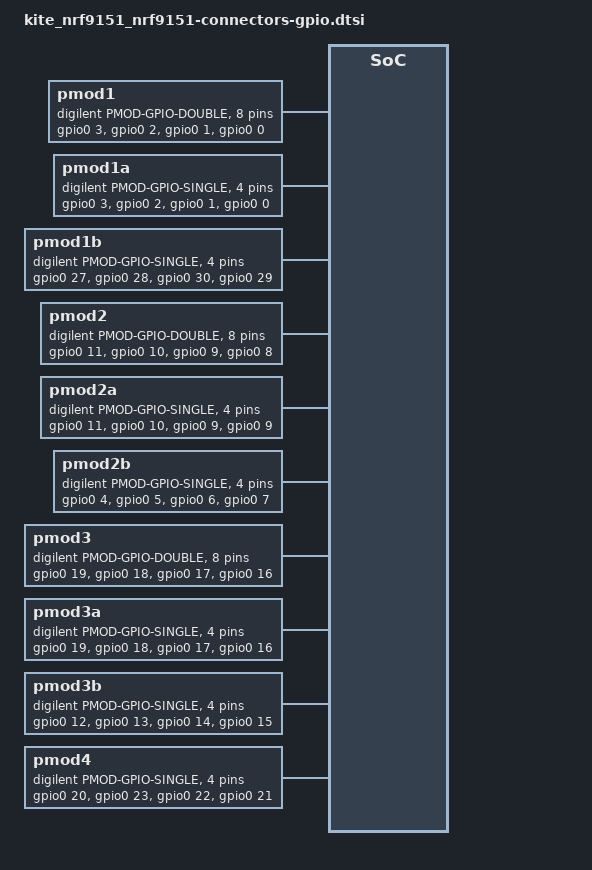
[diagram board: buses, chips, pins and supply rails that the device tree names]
/*
 * NOTE: Autogenerated file using gen-connectors-dtsi.py
 *
 * SPDX-License-Identifier: Apache-2.0
 */

/ {
	pmod1: pmod1-gpio {
		compatible = "digilent,pmod-gpio-double";
		#gpio-cells = <2>;
		gpio-map-mask = <0xffffffff 0xffffffc0>;
		gpio-map-pass-thru = <0 0x3f>;
		gpio-map = <0 0 &gpio0 3 0>,	/* IO1 */
			   <1 0 &gpio0 2 0>,	/* IO2 */
			   <2 0 &gpio0 1 0>,	/* IO3 */
			   <3 0 &gpio0 0 0>,	/* IO4 */
			   <4 0 &gpio0 27 0>,	/* IO5 */
			   <5 0 &gpio0 28 0>,	/* IO6 */
			   <6 0 &gpio0 30 0>,	/* IO7 */
			   <7 0 &gpio0 29 0>;	/* IO8 */
	};

	pmod1a: pmod1a-gpio {
		compatible = "digilent,pmod-gpio-single";
		#gpio-cells = <2>;
		gpio-map-mask = <0xffffffff 0xffffffc0>;
		gpio-map-pass-thru = <0 0x3f>;
		gpio-map = <0 0 &gpio0 3 0>,	/* IO1 */
			   <1 0 &gpio0 2 0>,	/* IO2 */
			   <2 0 &gpio0 1 0>,	/* IO3 */
			   <3 0 &gpio0 0 0>;	/* IO4 */
	};

	pmod1b: pmod1b-gpio {
		compatible = "digilent,pmod-gpio-single";
		#gpio-cells = <2>;
		gpio-map-mask = <0xffffffff 0xffffffc0>;
		gpio-map-pass-thru = <0 0x3f>;
		gpio-map = <0 0 &gpio0 27 0>,	/* IO1 */
			   <1 0 &gpio0 28 0>,	/* IO2 */
			   <2 0 &gpio0 30 0>,	/* IO3 */
			   <3 0 &gpio0 29 0>;	/* IO4 */
	};

	pmod2: pmod2-gpio {
		compatible = "digilent,pmod-gpio-double";
		#gpio-cells = <2>;
		gpio-map-mask = <0xffffffff 0xffffffc0>;
		gpio-map-pass-thru = <0 0x3f>;
		gpio-map = <0 0 &gpio0 11 0>,	/* IO1 */
			   <1 0 &gpio0 10 0>,	/* IO2 */
			   <2 0 &gpio0 9 0>,	/* IO3 */
			   <3 0 &gpio0 8 0>,	/* IO4 */
			   <4 0 &gpio0 4 0>,	/* IO5 */
			   <5 0 &gpio0 5 0>,	/* IO6 */
			   <6 0 &gpio0 6 0>,	/* IO7 */
			   <7 0 &gpio0 7 0>;	/* IO8 */
	};

	pmod2a: pmod2a-gpio {
		compatible = "digilent,pmod-gpio-single";
		#gpio-cells = <2>;
		gpio-map-mask = <0xffffffff 0xffffffc0>;
		gpio-map-pass-thru = <0 0x3f>;
		gpio-map = <0 0 &gpio0 11 0>,	/* IO1 */
			   <1 0 &gpio0 10 0>,	/* IO2 */
			   <2 0 &gpio0 9 0>,	/* IO3 */
			   <3 0 &gpio0 9 0>;	/* IO4 */
	};

	pmod2b: pmod2b-gpio {
		compatible = "digilent,pmod-gpio-single";
		#gpio-cells = <2>;
		gpio-map-mask = <0xffffffff 0xffffffc0>;
		gpio-map-pass-thru = <0 0x3f>;
		gpio-map = <0 0 &gpio0 4 0>,	/* IO1 */
			   <1 0 &gpio0 5 0>,	/* IO2 */
			   <2 0 &gpio0 6 0>,	/* IO3 */
			   <3 0 &gpio0 7 0>;	/* IO4 */
	};

	pmod3: pmod3-gpio {
		compatible = "digilent,pmod-gpio-double";
		#gpio-cells = <2>;
		gpio-map-mask = <0xffffffff 0xffffffc0>;
		gpio-map-pass-thru = <0 0x3f>;
		gpio-map = <0 0 &gpio0 19 0>,	/* IO1 */
			   <1 0 &gpio0 18 0>,	/* IO2 */
			   <2 0 &gpio0 17 0>,	/* IO3 */
			   <3 0 &gpio0 16 0>,	/* IO4 */
			   <4 0 &gpio0 12 0>,	/* IO5 */
			   <5 0 &gpio0 13 0>,	/* IO6 */
			   <6 0 &gpio0 14 0>,	/* IO7 */
			   <7 0 &gpio0 15 0>;	/* IO8 */
	};

	pmod3a: pmod3a-gpio {
		compatible = "digilent,pmod-gpio-single";
		#gpio-cells = <2>;
		gpio-map-mask = <0xffffffff 0xffffffc0>;
		gpio-map-pass-thru = <0 0x3f>;
		gpio-map = <0 0 &gpio0 19 0>,	/* IO1 */
			   <1 0 &gpio0 18 0>,	/* IO2 */
			   <2 0 &gpio0 17 0>,	/* IO3 */
			   <3 0 &gpio0 16 0>;	/* IO4 */
	};

	pmod3b: pmod3b-gpio {
		compatible = "digilent,pmod-gpio-single";
		#gpio-cells = <2>;
		gpio-map-mask = <0xffffffff 0xffffffc0>;
		gpio-map-pass-thru = <0 0x3f>;
		gpio-map = <0 0 &gpio0 12 0>,	/* IO1 */
			   <1 0 &gpio0 13 0>,	/* IO2 */
			   <2 0 &gpio0 14 0>,	/* IO3 */
			   <3 0 &gpio0 15 0>;	/* IO4 */
	};

	pmod4: pmod4-gpio {
		compatible = "digilent,pmod-gpio-single";
		#gpio-cells = <2>;
		gpio-map-mask = <0xffffffff 0xffffffc0>;
		gpio-map-pass-thru = <0 0x3f>;
		gpio-map = <0 0 &gpio0 20 0>,	/* IO1 */
			   <1 0 &gpio0 23 0>,	/* IO2 */
			   <2 0 &gpio0 22 0>,	/* IO3 */
			   <3 0 &gpio0 21 0>;	/* IO4 */
	};

};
